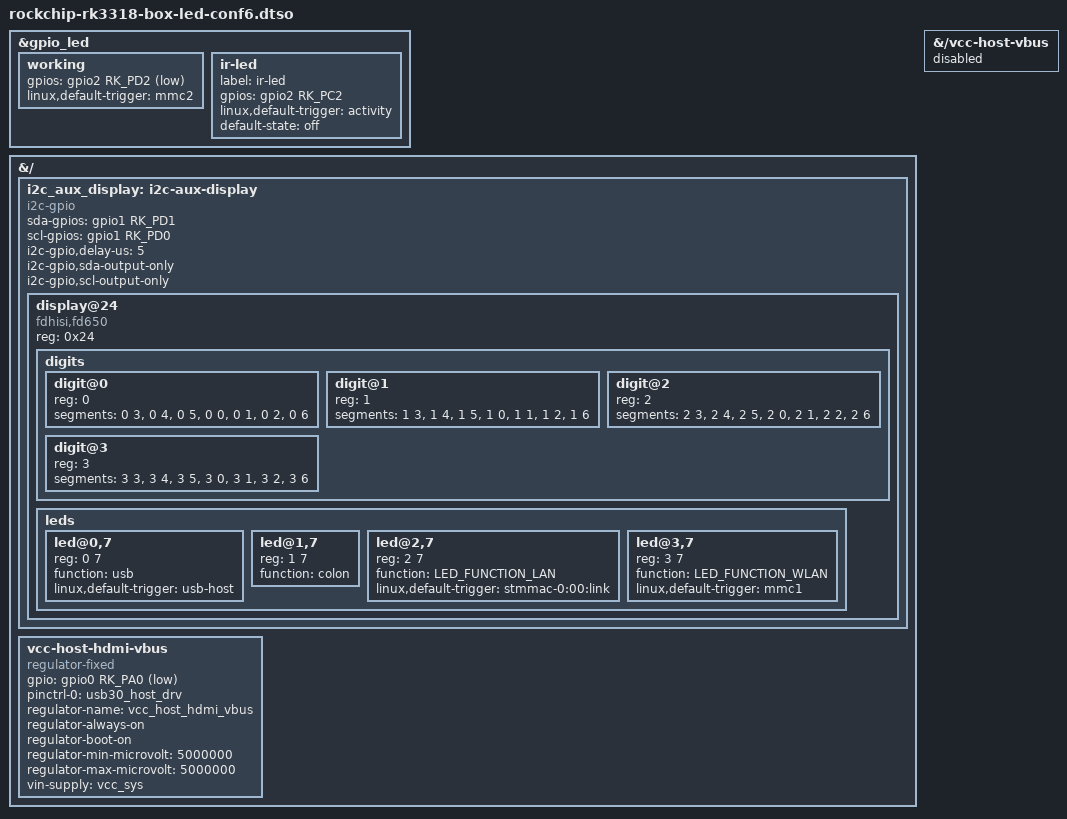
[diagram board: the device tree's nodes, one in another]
/dts-v1/;
/plugin/;

#include <dt-bindings/gpio/gpio.h>
#include <dt-bindings/leds/common.h>
#include <dt-bindings/pinctrl/rockchip.h>

/**
 * T98_RK3318 (Hongtop H50)
 */

&gpio_led {

	working {
		gpios = <&gpio2 RK_PD2 GPIO_ACTIVE_LOW>;
		linux,default-trigger = "mmc2"; /* usually timer but here will alternate a red and blue led */
	};
        ir-led {
                label = "ir-led";
                gpios = <&gpio2 RK_PC2 GPIO_ACTIVE_HIGH>;
                linux,default-trigger = "activity"; /* blue led close to ir receiver */
                default-state = "off";
            };
};

&{/} {

	i2c_aux_display: i2c-aux-display {

		compatible = "i2c-gpio";
		sda-gpios = <&gpio1 RK_PD1 (GPIO_ACTIVE_HIGH|GPIO_OPEN_DRAIN)>;
		scl-gpios = <&gpio1 RK_PD0 (GPIO_ACTIVE_HIGH|GPIO_OPEN_DRAIN)>;
		i2c-gpio,delay-us = <5>;
		i2c-gpio,sda-output-only;
		i2c-gpio,scl-output-only;
		#address-cells = <1>;
		#size-cells = <0>;

		display@24 {
			compatible = "fdhisi,fd650" , "titanmec,tm1650"; /* do not remove tm1650 */
			reg = <0x24>;

			digits {
				#address-cells = <1>;
				#size-cells = <0>;

				digit@0 {
					reg = <0>;
					segments = <0 3>, <0 4>, <0 5>, <0 0>, <0 1>, <0 2>, <0 6>;
				};

				digit@1 {
					reg = <1>;
					segments = <1 3>, <1 4>, <1 5>, <1 0>, <1 1>, <1 2>, <1 6>;
				};

				digit@2 {
					reg = <2>;
					segments = <2 3>, <2 4>, <2 5>, <2 0>, <2 1>, <2 2>, <2 6>;
				};

				digit@3{
					reg = <3>;
					segments = <3 3>, <3 4>, <3 5>, <3 0>, <3 1>, <3 2>, <3 6>;
				};

			};

			leds {
				#address-cells = <2>;
				#size-cells = <0>;

				led@0,7 {
					reg = <0 7>;
					function = "usb";
					linux,default-trigger = "usb-host";
                                        
				};

				led@1,7 {
					reg = <1 7>;
					function = "colon";
				};

				led@2,7 {
					reg = <2 7>;
					function = LED_FUNCTION_LAN;
					linux,default-trigger = "stmmac-0:00:link";
				};

				led@3,7 {
					reg = <3 7>;
					function = LED_FUNCTION_WLAN;
					linux,default-trigger = "mmc1";

				};

			};

		};

	};

};
/* modify existimg regulator to power on HDMI */
&{/vcc-host-vbus} {
    status = "disabled";
};

&{/} {
	vcc-host-hdmi-vbus {
	        compatible = "regulator-fixed";
	        gpio = <&gpio0 RK_PA0 GPIO_ACTIVE_LOW>;
	        pinctrl-names = "default";
	        pinctrl-0 = <&usb30_host_drv>;
	        regulator-name = "vcc_host_hdmi_vbus";
	        regulator-always-on;
	        regulator-boot-on;
	        regulator-min-microvolt = <5000000>;
	        regulator-max-microvolt = <5000000>;
	        vin-supply = <&vcc_sys>;
   	 };

   };
